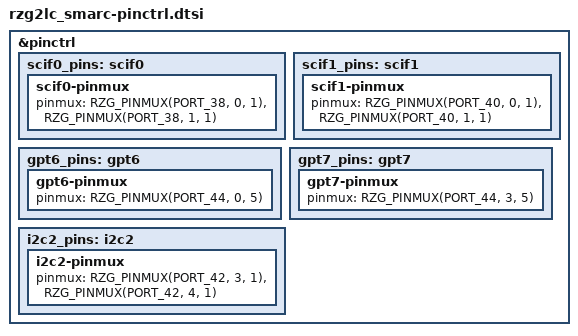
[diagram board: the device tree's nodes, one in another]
/*
 * Copyright (c) 2025 Renesas Electronics Corporation
 * SPDX-License-Identifier: Apache-2.0
 */

#include <zephyr/dt-bindings/gpio/gpio.h>
#include <zephyr/dt-bindings/pinctrl/renesas/pinctrl-rzg2-common.h>

&pinctrl {
	/omit-if-no-ref/ scif0_pins: scif0 {
		scif0-pinmux {
			pinmux = <RZG_PINMUX(PORT_38, 0, 1)>, /* TXD */
				 <RZG_PINMUX(PORT_38, 1, 1)>; /* RXD */
		};
	};

	/omit-if-no-ref/ scif1_pins: scif1 {
		scif1-pinmux {
			pinmux = <RZG_PINMUX(PORT_40, 0, 1)>, /* TXD */
				 <RZG_PINMUX(PORT_40, 1, 1)>; /* RXD */
		};
	};

	/omit-if-no-ref/ gpt6_pins: gpt6 {
		gpt6-pinmux {
			pinmux = <RZG_PINMUX(PORT_44, 0, 5)>; /* GTIOCA */
		};
	};

	/omit-if-no-ref/ gpt7_pins: gpt7 {
		gpt7-pinmux {
			pinmux = <RZG_PINMUX(PORT_44, 3, 5)>; /* GTIOCB */
		};
	};

	/omit-if-no-ref/ i2c2_pins: i2c2 {
		i2c2-pinmux {
			pinmux = <RZG_PINMUX(PORT_42, 3, 1)>, /* SDA */
				 <RZG_PINMUX(PORT_42, 4, 1)>; /* SCL */
		};
	};
};
